# MDR32FG16S1QI register map
Vendor: Milandr; File version: 1.0
CPU: CM3 r1p1, little endian, MPU, no FPU, 3 interrupt priority bits
Registers are 32-bit, read-write, reset 0x0 unless marked. A register's access mark holds for its fields unless they carry their own. Offsets are from the block's base; lines under a group give offsets from that group; [hi:lo] are bit positions; {n}, {i} and the like mark numbered series; 'fields as' and 'values as' point back to an identical list; <NAME> marks a mode.

## Memory map
0x30000040 MDR_BSP1 size 0x10 — BSP1
0x30000050 MDR_BSP2 size 0x10 — BSP2
0x30000060 MDR_BSP3 size 0x10 — BSP3
0x30000080 MDR_CRPT size 0x20 — CRPT
0x300000C0 MDR_DMA_DSP size 0x40 — DMA controller registers
0x40000000 MDR_SSP3 size 0x1000 — SSP3
0x40008000 MDR_SSP4 size 0x1000 — SSP4
0x40010000 MDR_USB size 0x1000 — USB interface controller registers
0x40018000 MDR_EEPROM size 0x1000 — Flash programm memory interface controller registers
0x40020000 MDR_RST_CLK size 0x1000 — RST_CLK
0x40028000 MDR_DMA size 0x1000 — DMA controller registers
0x40030000 MDR_UART1 size 0x1000 — UART1 interface controller registers
0x40038000 MDR_UART2 size 0x1000 — UART2 interface controller registers
0x40040000 MDR_SSP1 size 0x1000 — SSP1 interface controller registers
0x40048000 MDR_SDIO size 0x2C — SDIO Controller
0x40050000 MDR_I2C size 0x1000 — I2C interface controller registers
0x40058000 MDR_POWER size 0x1000 — POWER
0x40060000 MDR_WWDG size 0x1000 — WWDT
0x40068000 MDR_IWDG size 0x1000 — IWDT
0x40070000 MDR_TIMER1 size 0x1000 — TIMER1
0x40078000 MDR_TIMER2 size 0x1000 — TIMER2
0x40080000 MDR_TIMER3 size 0x1000 — TIMER3
0x40088000 MDR_ADC size 0x1000 — ADC
0x40090000 MDR_DAC size 0x1000 — DAC
0x40098000 MDR_COMP size 0x1000 — COMPARATOR
0x400A0000 MDR_SSP2 size 0x1000 — SSP2
0x400A8000 MDR_PORTA size 0x1000 — PORTA
0x400B0000 MDR_PORTB size 0x1000 — PORTB
0x400B8000 MDR_PORTC size 0x1000 — PORTC
0x400C0000 MDR_PORTD size 0x1000 — PORTD
0x400C8000 MDR_PORTE size 0x1000 — PORTE
0x400D0000 MDR_UART3 size 0x1000 — UART3 interface controller registers
0x400D8000 MDR_BKP size 0x1000 — BACKUP
0x400E8000 MDR_PORTF size 0x1000 — PORTF
0x400F0000 MDR_EBC size 0x1000 — EBC

## Interrupts
0 SSP3_IRQ (MDR_SSP3)
1 SSP4_IRQ (MDR_SSP4)
2 USB_IRQ (MDR_USB)
3 McBSP1_IRQ (MDR_BSP1)
4 McBSP2_IRQ (MDR_BSP2)
5 DMA_IRQ (MDR_DMA)
6 UART1_IRQ (MDR_UART1)
7 UART2_IRQ (MDR_UART2)
8 SSP1_IRQ (MDR_SSP1)
9 McBSP3_IRQ (MDR_BSP3)
10 I2C_IRQ (MDR_I2C)
11 POWER_IRQ (MDR_POWER)
12 WWDG_IRQ (MDR_WWDG)
13 DMA_DSP_IRQ (MDR_DMA_DSP)
14 Timer1_IRQ (MDR_TIMER1)
15 Timer2_IRQ (MDR_TIMER2)
16 Timer3_IRQ (MDR_TIMER3)
17 ADC_IRQ (MDR_ADC)
18 SDIO_IRQ (MDR_SDIO)
19 COMPARATOR_IRQ (MDR_COMP)
20 SSP2_IRQ (MDR_SSP2)
21 AUDIO_CODEC_DSP_IRQ (MDR_RST_CLK)
22 CRPT_IRQ (MDR_CRPT)
23 TIMER_DSP_IRQ (MDR_DMA)
24 DSP_CORE_IRQ (MDR_DMA)
25 DSP_STATE_IRQ (MDR_DMA)
26 UART3_IRQ (MDR_UART3)
27 BACKUP_IRQ (MDR_BKP)
28 EXT_INT1_IRQ (MDR_PORTA)
29 EXT_INT2_IRQ (MDR_PORTA)
30 EXT_INT3_IRQ (MDR_PORTA)
31 EXT_INT4_IRQ (MDR_PORTA)

## MDR_USB — USB interface controller registers
Base 0x40010000
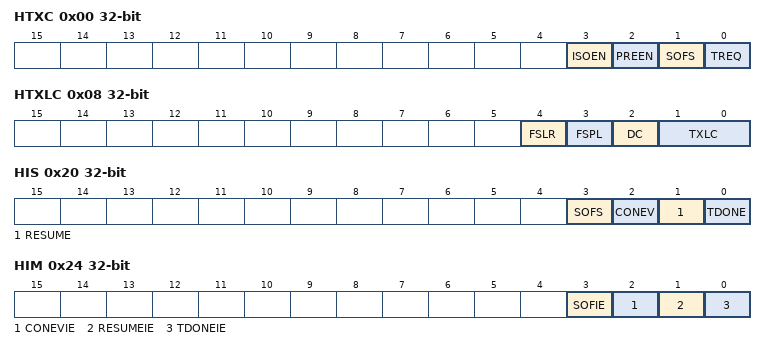
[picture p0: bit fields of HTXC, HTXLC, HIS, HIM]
0x00 HTXC — USB HTXC Register
  [3] ISOEN, [2] PREEN, [1] SOFS, [0] TREQ
0x04 HTXT — USB HTXT Register
  [1:0] TTYPE
0x08 HTXLC — USB HTXLC Register
  [4] FSLR, [3] FSPL, [2] DC, [1:0] TXLC
0x0C HTXSE
  [0] SOFEN
0x10 HTXA
  [6:0] DEVADDR
0x14 HTXE
  [3:0] EPADDR
0x18 HFN_L
  [7:0] FNUM
0x1C HFN_H
  [2:0] FNUM
0x20 HIS — USB_HIS Register
  [3] SOFS, [2] CONEV, [1] RESUME, [0] TDONE
0x24 HIM — USB_HIM Register
  [3] SOFIE, [2] CONEVIE, [1] RESUMEIE, [0] TDONEIE
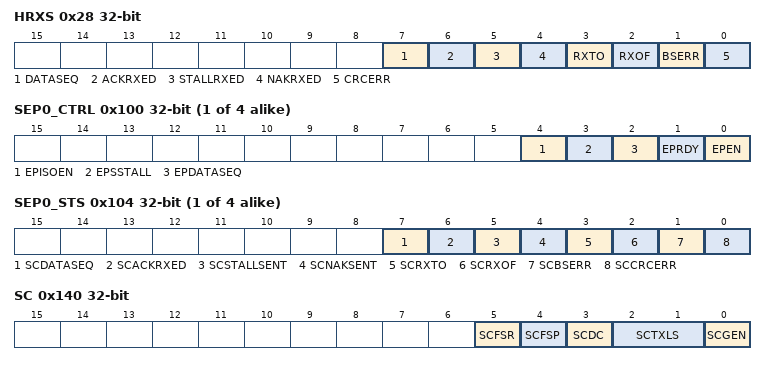
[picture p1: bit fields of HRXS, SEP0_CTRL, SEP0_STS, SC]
0x28 HRXS — USB_HRXS Register
  [7] DATASEQ, [6] ACKRXED, [5] STALLRXED, [4] NAKRXED, [3] RXTO, [2] RXOF, [1] BSERR, [0] CRCERR
0x2C HRXP
  [3:0] RPID
0x30 HRXA
  [6:0] RADDR
0x34 HRXE
  [3:0] RENDP
0x38 HRXCS
  [1:0] RXLS
0x3C HSTM
  [7:0] HSTM
0x80 HRXFD
  [7:0] RXFIFODATA
0x88 HRXFDC_L
  [7:0] FIFODATACOUNT
0x8C HRXFDC_H
  [7:0] FIFODATACOUNT
0x90 HRXFC
  [0] FIFOFORCEEMPTY
0xC0 HTXFD
  [7:0] TXFIFODATA
0xD0 HTXFC
  [0] FIFOFORCEEMPTY
{0x100+0x10*i} SEP{i}_CTRL (i=0..3) — USB_SEP Control Register
  [4] EPISOEN, [3] EPSSTALL, [2] EPDATASEQ, [1] EPRDY, [0] EPEN
{0x104+0x10*i} SEP{i}_STS (i=0..3) — USB_SEP Status Register
  [7] SCDATASEQ, [6] SCACKRXED, [5] SCSTALLSENT, [4] SCNAKSENT, [3] SCRXTO, [2] SCRXOF, [1] SCBSERR, [0] SCCRCERR
{0x108+0x10*i} SEP{i}_TS (i=0..3)
  [1:0] SCTTYPE
{0x10C+0x10*i} SEP{i}_NTS (i=0..3)
  [1:0] NTTYPE
0x140 SC — USB_SC Register
  [5] SCFSR, [4] SCFSP, [3] SCDC, [2:1] SCTXLS, [0] SCGEN
0x144 SLS
  [1:0] SCRXLS
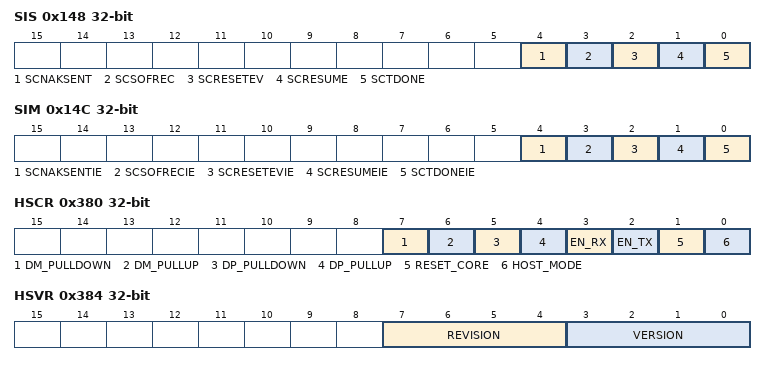
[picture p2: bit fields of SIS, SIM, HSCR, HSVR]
0x148 SIS — USB_SIS Register
  [4] SCNAKSENT, [3] SCSOFREC, [2] SCRESETEV, [1] SCRESUME, [0] SCTDONE
0x14C SIM — USB_SIM Register
  [4] SCNAKSENTIE, [3] SCSOFRECIE, [2] SCRESETEVIE, [1] SCRESUMEIE, [0] SCTDONEIE
0x150 SA
  [6:0] SCDEVADDR
0x154 SFN_L
  [7:0] FRAMENUM
0x158 SFN_H
  [2:0] FRAMENUM
{0x180+0x80*i} SEP_FIFO{i}_RXFD (i=0..3)
  [7:0] RXFIFODATA
{0x188+0x80*i} SEP_FIFO{i}_RXFDC_L (i=0..3)
  [7:0] FIFODATACOUNT
{0x18C+0x80*i} SEP_FIFO{i}_RXFDC_H (i=0..3)
  [7:0] FIFODATACOUNT
{0x190+0x80*i} SEP_FIFO{i}_RXFC (i=0..3)
  [0] FIFOFORCEEMPTY
{0x1C0+0x80*i} SEP_FIFO{i}_TXFD (i=0..3)
  [7:0] TXFIFODATA
{0x1D0+0x80*i} SEP_FIFO{i}_TXFDC (i=0..3)
  [0] FIFOFORCEEMPTY
0x380 HSCR — USB_HSCR Register
  [7] DM_PULLDOWN, [6] DM_PULLUP, [5] DP_PULLDOWN, [4] DP_PULLUP, [3] EN_RX, [2] EN_TX, [1] RESET_CORE, [0] HOST_MODE
0x384 HSVR — USB_HSVR Register
  [7:4] REVISION, [3:0] VERSION
